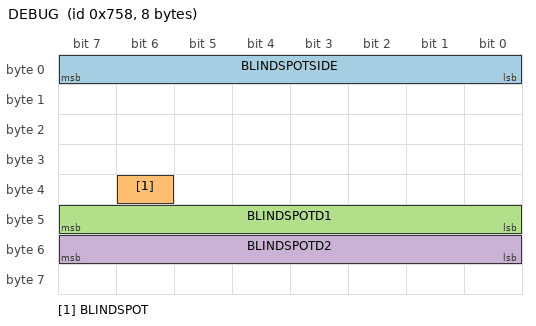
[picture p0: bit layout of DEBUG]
BO_ 1880 DEBUG: 8 XXX
 SG_ BLINDSPOTSIDE : 7|8@0+ (1,0) [0|255] "" XXX
 SG_ BLINDSPOT : 38|1@0+ (1,0) [0|15] "" XXX
 SG_ BLINDSPOTD1 : 47|8@0+ (1,0) [0|255] "" XXX
 SG_ BLINDSPOTD2 : 55|8@0+ (1,0) [0|255] "" XXX
